# MCXN947_cm33_core0 register map
Vendor: nxp.com; File version: 1.0
CPU: CM33 r2p0, little endian, MPU, FPU, VTOR, 3 interrupt priority bits
Registers are 32-bit, read-write, reset 0x0 unless marked. A register's access mark holds for its fields unless they carry their own. Offsets are from the block's base; [hi:lo] are bit positions; lines under a group give offsets from that group; {n}, {i} and the like mark numbered series; 'fields as' and 'values as' point back to an identical list.

## VBAT0 — VBAT
Base 0x40059000
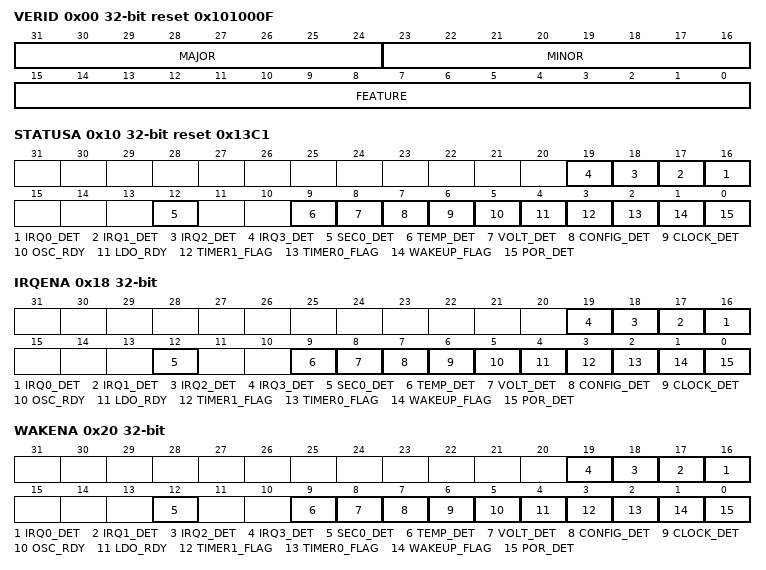
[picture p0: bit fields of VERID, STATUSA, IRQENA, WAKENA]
0x00 VERID ro reset 0x101000F — Version ID
  [31:24] MAJOR — Major Version Number
  [23:16] MINOR — Minor Version Number
  [15:0] FEATURE — Feature Specification Number
0x10 STATUSA reset 0x13C1
  [n+16] IRQ{n}_DET ro (n=0..3) — Interrupt {n} Detect
    0=CLR (Not asserted); 1=SET (Asserted)
  [12] SEC0_DET write-1-clears — Input 0 Detect
    0=CLR (Security input 0 not detected); 1=SET (Security input 0 detected)
  [9] TEMP_DET write-1-clears — Temperature Detect
    0=CLR (Temperature error not detected); 1=SET (Temperature error detected)
  [8] VOLT_DET write-1-clears — Voltage Detect
    on read: 0=CLR (Not detected); 1=SET (Detected)
  [7] CONFIG_DET write-1-clears — Configuration Detect Flag
    on read: 0=CLR (Not detected); 1=SET (Detected)
  [6] CLOCK_DET write-1-clears — Clock Detect
    0=CLR (Clock error not detected); 1=SET (Clock error detected)
  [5] OSC_RDY ro — OSC32k Ready
    0=CLR (Disabled (clock not ready)); 1=SET (Enabled (clock ready))
  [4] LDO_RDY ro — LDO Ready
    0=CLR (Disabled (not ready)); 1=SET (Enabled (ready))
  [3] TIMER1_FLAG write-1-clears — Bandgap Timer 1 Flag
    on read: 0=CLR (Not reached); 1=SET (Reached)
  [2] TIMER0_FLAG write-1-clears — Bandgap Timer 0 Flag
    on read: 0=CLR (Not reached); 1=SET (Reached)
  [1] WAKEUP_FLAG write-1-clears — Wakeup Pin Flag
    on read: 0=CLR (Not asserted); 1=SET (Asserted)
  [0] POR_DET write-1-clears — POR Detect Flag
    on read: 0=CLR (Not reset); 1=SET (Reset)
0x14 STATUSB reset 0xF003E write-0-clears
  [19:0] INVERSE write-0-clears — Inverse value
0x18 IRQENA — Interrupt Enable A
  [n+16] IRQ{n}_DET (n=0..3) — Interrupt {n} Detect
    0=DISABLE; 1=ENABLE
  [12] SEC0_DET — Input 0 Detect
    0=DISABLE; 1=ENABLE
  [9] TEMP_DET — Temperature Detect
    0=DISABLE (Interrupt disabled); 1=ENABLE (Interrupt enabled)
  [8] VOLT_DET — Voltage Detect
    0=DISABLE; 1=ENABLE
  [7] CONFIG_DET — Configuration Detect
    0=CLR (Disable); 1=SET (Enable)
  [6] CLOCK_DET — Clock Detect
    0=DISABLE; 1=ENABLE
  [5] OSC_RDY — OSC32k Ready
    0=DISABLE; 1=ENABLE
  [4] LDO_RDY — LDO Ready
    0=DISABLE; 1=ENABLE
  [3] TIMER1_FLAG — Bandgap Timer 2
    0=DISABLE; 1=ENABLE
  [2] TIMER0_FLAG — Bandgap Timer 0
    0=DISABLE; 1=ENABLE
  [1] WAKEUP_FLAG — Wakeup Pin Flag
    0=CLR (Disable); 1=SET (Enable)
  [0] POR_DET — POR Detect
    0=DISABLE; 1=ENABLE
0x1C IRQENB reset 0xFFFFF — Interrupt Enable B
  [19:0] INVERSE — Inverse Value
0x20 WAKENA — Wake-up Enable A
  [n+16] IRQ{n}_DET (n=0..3) — Interrupt {n} Detect
    0=DISABLE; 1=ENABLE
  [12] SEC0_DET — Input 0 Detect
    0=DISABLE (Disabled); 1=ENABLE (Enabled)
  [9] TEMP_DET — Temperature Detect
    0=DISABLE; 1=ENABLE
  [8] VOLT_DET — Voltage Detect
    0=DISABLE; 1=ENABLE
  [7] CONFIG_DET — Configuration Detect
    0=CLR (Disable); 1=SET (Enable)
  [6] CLOCK_DET — Clock Detect
    0=DISABLE; 1=ENABLE
  [5] OSC_RDY — OSC32K Ready
    0=DISABLE; 1=ENABLE
  [4] LDO_RDY — LDO Ready
    0=DISABLE; 1=ENABLE
  [3] TIMER1_FLAG — Bandgap Timer 2
    0=DISABLE; 1=ENABLE
  [2] TIMER0_FLAG — Bandgap Timer 0
    0=DISABLE; 1=ENABLE
  [1] WAKEUP_FLAG — Wake-up Pin Flag
    0=CLR (Disable); 1=SET (Enable)
  [0] POR_DET — POR Detect
    0=DISABLE; 1=ENABLE
0x24 WAKENB reset 0xFFFFF — Wake-up Enable B
  [19:0] INVERSE — Inverse Value
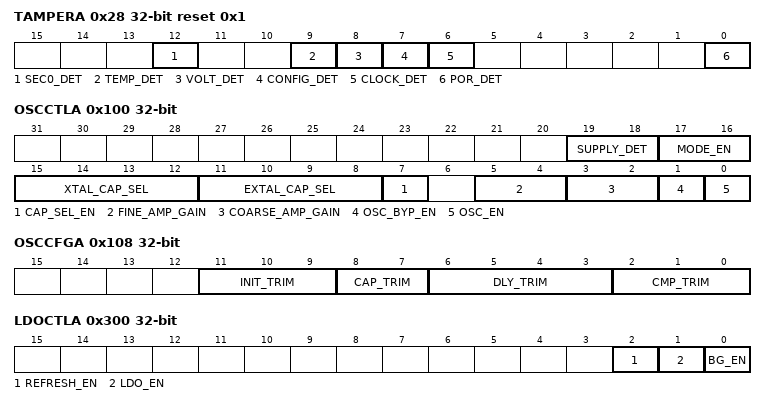
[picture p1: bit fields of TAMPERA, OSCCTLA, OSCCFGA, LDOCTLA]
0x28 TAMPERA reset 0x1 — Tamper Enable A
  [12] SEC0_DET — Input 0 Detect
    0=DISABLE (Tamper disabled); 1=ENABLE (Tamper enabled)
  [9] TEMP_DET — Temperature Detect
    0=DISABLE (Tamper disabled); 1=ENABLE (Tamper enabled)
  [8] VOLT_DET — Voltage Detect
    0=DISABLE (Tamper disabled); 1=ENABLE (Tamper enabled)
  [7] CONFIG_DET — Configuration Detect
    0=CLR (Tamper disabled); 1=SET (Tamper enabled)
  [6] CLOCK_DET — Clock Detect
    0=DISABLE (Tamper disabled); 1=ENABLE (Tamper enabled)
  [0] POR_DET — POR Detect
    0=DISABLE (Tamper disabled); 1=ENABLE (Tamper enabled)
0x2C TAMPERB reset 0xFFC0 — Tamper Enable B
  [15:0] INVERSE — Inverse value
0x30 LOCKA
  [0] LOCK
    0=DISABLE (Disables lock); 1=ENABLE (Enables lock. Cleared by VBAT POR.)
0x34 LOCKB reset 0x1
  [0] LOCK
    0=ENABLE (Enables lock); 1=DISABLE (Disables lock)
0x38 WAKECFG — Wake-up Configuration
  [0] OUT — Output
    0=ON (Logic zero (asserted)); 1=OFF (Logic one)
0x100 OSCCTLA — Oscillator Control A
  [19:18] SUPPLY_DET — Supply Detector Trim
  [17:16] MODE_EN — Mode Enable
    0=HP (Transconductance Oscillator mode); 1=LP (Low-Power Backup mode); 2=SW (Low-Power Switched mode)
  [15:12] XTAL_CAP_SEL — Crystal Load Capacitance Selection
    0=SEL0 (0 pF); 1=SEL2 (2 pF); 2=SEL4 (4 pF); 3=SEL6 (6 pF); 4=SEL8 (8 pF); 5=SEL10 (10 pF); 6=SEL12 (12 pF); 7=SEL14 (14 pF); 8=SEL16 (16 pF); 9=SEL18 (18 pF); 10=SEL20 (20 pF); 11=SEL22 (22 pF); 12=SEL24 (24 pF); 13=SEL26 (26 pF); 14=SEL28 (28 pF); 15=SEL30 (30 pF)
  [11:8] EXTAL_CAP_SEL — Crystal Load Capacitance Selection
    values as XTAL_CAP_SEL
  [7] CAP_SEL_EN — Crystal Load Capacitance Selection Enable
    0=DISABLE; 1=ENABLE
  [5:4] FINE_AMP_GAIN — Amplifier Gain Fine Adjustment
    0=AGC200 (200 mV)
  [3:2] COARSE_AMP_GAIN — Amplifier Gain Coarse Adjustment
    0=GAIN05 (0.5 uA/V); 1=GAIN10 (1.0 uA/V); 2=GAIN18 (1.8 uA/V); 3=GAIN33 (3.3 uA/V)
  [1] OSC_BYP_EN — Crystal Oscillator Bypass Enable
    0=DISABLE (Does not bypass); 1=ENABLE (Bypass)
  [0] OSC_EN — Crystal Oscillator Enable
    0=DISABLE; 1=ENABLE
0x104 OSCCTLB reset 0xFFFFF — Oscillator Control B
  [19:0] INVERSE — Inverse Value
0x108 OSCCFGA — Oscillator Configuration A
  [11:9] INIT_TRIM — Initialization Trim
    0=SEL0 (8 s); 1=SEL1 (4 s); 2=SEL2 (2 s); 3=SEL3 (1 s); 4=SEL4 (0.5 s); 5=SEL5 (0.25 s); 6=SEL6 (0.125 s); 7=SEL7 (0.5 ms)
  [8:7] CAP_TRIM — Capacitor Trim
  [6:3] DLY_TRIM — Delay Trim
  [2:0] CMP_TRIM — Comparator Trim
0x10C OSCCFGB reset 0xFFF — Oscillator Configuration B
  [11:0] INVERSE — Inverse Value
0x118 OSCLCKA — Oscillator Lock A
  [0] LOCK
    0=DISABLE (Do not block); 1=ENABLE (Block)
0x11C OSCLCKB reset 0x1 — Oscillator Lock B
  [0] LOCK
    0=ENABLE (Block); 1=DISABLE (Do not block)
0x120 OSCCLKE — Oscillator Clock Enable
  [3:0] CLKE — Clock Enable
0x200 FROCTLA reset 0x1 — FRO16K Control A
  [0] FRO_EN — FRO16K Enable
    0=DISABLE; 1=ENABLE
0x204 FROCTLB — FRO16K Control B
  [0] INVERSE — Inverse Value
0x218 FROLCKA — FRO16K Lock A
  [0] LOCK
    0=DISABLE (Do not block); 1=ENABLE (Block)
0x21C FROLCKB reset 0x1 — FRO16K Lock B
  [0] LOCK
    0=ENABLE (Block); 1=DISABLE (Do not block)
0x220 FROCLKE — FRO16K Clock Enable
  [3:0] CLKE — Clock Enable
0x300 LDOCTLA — LDO_RAM Control A
  [all] fields
    0=DISABLE; 1=ENABLE
  [2] REFRESH_EN — Refresh Enable
  [1] LDO_EN — LDO Enable
  [0] BG_EN — Bandgap Enable
0x304 LDOCTLB reset 0x7 — LDO_RAM Control B
  [2:0] INVERSE — Inverse Value
0x318 LDOLCKA — LDO_RAM Lock A
  [0] LOCK
    0=DISABLE (Do not block); 1=ENABLE (Block)
0x31C LDOLCKB reset 0x1 — LDO_RAM Lock B
  [0] LOCK
    0=ENABLE (Block); 1=DISABLE (Do not block)
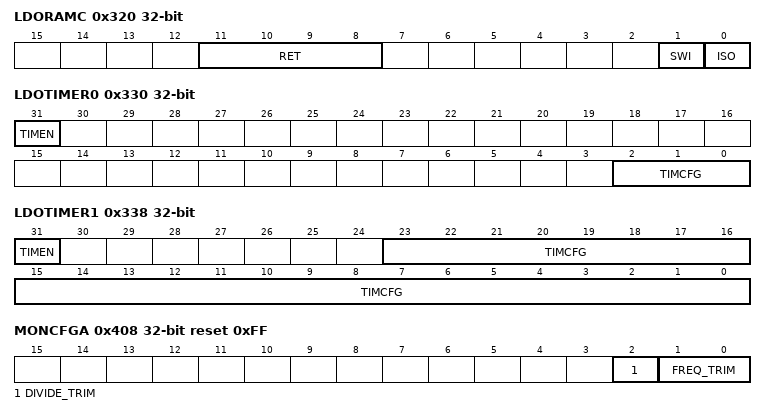
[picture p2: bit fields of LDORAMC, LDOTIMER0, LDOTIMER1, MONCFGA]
0x320 LDORAMC — RAM Control
  [11:8] RET — Retention
    0=DISABLE (Retained); 1=ENABLE (Not retained)
  [1] SWI — Switch SRAM
    0=DISABLE (Supply follows the chip power modes); 1=ENABLE (LDO_RAM powers the array)
  [0] ISO — Isolate SRAM
    0=DISABLE (State follows the chip power modes); 1=ENABLE (Isolates SRAM and places it in Low-Power Retention mode)
0x330 LDOTIMER0 — Bandgap Timer 0
  [31] TIMEN — Bandgap Timeout Period Enable
    0=DISABLE; 1=ENABLE
  [2:0] TIMCFG — Timeout Configuration
    0=CFG1000 (1 s); 1=CFG500 (500 ms); 2=CFG250 (250 ms); 3=CFG125 (125 ms); 4=CFG62 (62.5 ms); 5=CFG31 (31.25 ms); 6=CFG15 (15.625 ms); 7=CFG7 (7.8125 ms)
0x338 LDOTIMER1 — Bandgap Timer 1
  [31] TIMEN — Bandgap Timeout Period Enable
    0=DISABLE; 1=ENABLE
  [23:0] TIMCFG — Timeout Configuration
0x400 MONCTLA — CLKMON Control A
  [0] MON_EN — CLKMON Enable
    0=DISABLE (CLKMON is disabled); 1=ENABLE (CLKMON is enabled)
0x404 MONCTLB reset 0x1 — CLKMON Control B
  [0] INVERSE — Inverse value
0x408 MONCFGA reset 0xFF — CLKMON Configuration A
  [2] DIVIDE_TRIM
    0=CFG0 (Clock monitor operates at 1 kHz); 1=CFG1 (Clock monitor operates at 64 Hz)
  [1:0] FREQ_TRIM — Frequency Trim
    0=CFG0 (Clock monitor asserts 2 cycle after expected edge); 1=CFG1 (Clock monitor asserts 4 cycles after expected edge); 2=CFG2 (Clock monitor asserts 6 cycles after expected edge); 3=CFG3 (Clock monitor asserts 8 cycles after expected edge)
0x40C MONCFGB — CLKMON Configuration B
  [7:0] INVERSE — Inverse value
0x418 MONLCKA — CLKMON Lock A
  [0] LOCK
    0=DISABLE (Lock is disabled); 1=ENABLE (Lock is enabled)
0x41C MONLCKB reset 0x1 — CLKMON Lock B
  [0] LOCK
    0=ENABLE (Lock is enabled); 1=DISABLE (Lock is disabled)
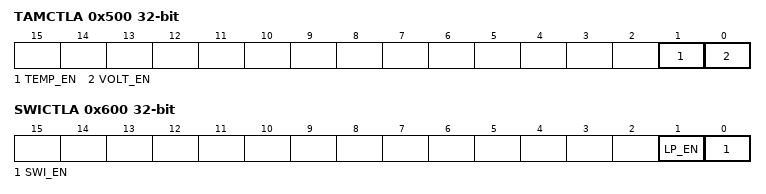
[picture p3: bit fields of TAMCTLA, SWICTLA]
0x500 TAMCTLA — TAMPER Control A
  [1] TEMP_EN — Temperature Detect Enable
    0=DISABLE (Temperature detect is disabled); 1=ENABLE (Temperature detect is enabled)
  [0] VOLT_EN — Voltage Detect Enable
    0=DISABLE (Voltage detect is disabled); 1=ENABLE (Voltage detect is enabled)
0x504 TAMCTLB reset 0xF — TAMPER Control B
  [3:0] INVERSE — Inverse value
0x518 TAMLCKA — TAMPER Lock A
  fields as MONLCKA
0x51C TAMLCKB reset 0x1 — TAMPER Lock B
  fields as MONLCKB
0x600 SWICTLA — Switch Control A
  [1] LP_EN — Low Power Enable
    0=DISABLE (VDD_BAT always supplies VBAT modules in low-power modes); 1=ENABLE (VDD_SYS always supplies VBAT modules if SWI_EN is also 1)
  [0] SWI_EN — Switch Enable
    0=DISABLE (VDD_BAT); 1=ENABLE (VDD_SYS)
0x604 SWICTLB reset 0x3 — Switch Control B
  [1:0] INVERSE — Inverse Value
0x618 SWILCKA — Switch Lock A
  [0] LOCK
    0=DISABLE (Do not block); 1=ENABLE (Block)
0x61C SWILCKB reset 0x1 — Switch Lock B
  [0] LOCK
    0=ENABLE (Block); 1=DISABLE (Do not block)
{0x700+8i} WAKEUP[{i}] (i=0..1) group
  0x00 WAKEUPA — Wakeup 0 Register A
    [31:0] REG — Register
  0x04 WAKEUPB reset 0xFFFFFFFF — Wakeup 0 Register B
    [31:0] INVERSE — Inverse value
0x7F8 WAKLCKA — Wakeup Lock A
  fields as MONLCKA
0x7FC WAKLCKB reset 0x1 — Wakeup Lock B
  fields as MONLCKB
